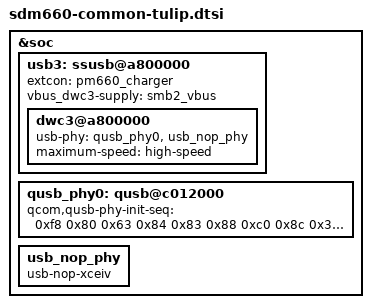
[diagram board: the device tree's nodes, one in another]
/* Copyright (c) 2016-2017, The Linux Foundation. All rights reserved.
 * Copyright (C) 2018 XiaoMi, Inc.
 *
 * This program is free software; you can redistribute it and/or modify
 * it under the terms of the GNU General Public License version 2 and
 * only version 2 as published by the Free Software Foundation.
 *
 * This program is distributed in the hope that it will be useful,
 * but WITHOUT ANY WARRANTY; without even the implied warranty of
 * MERCHANTABILITY or FITNESS FOR A PARTICULAR PURPOSE.  See the
 * GNU General Public License for more details.
 */

&soc {
	usb3: ssusb@a800000 {
		extcon = <&pm660_charger>;
		vbus_dwc3-supply = <&smb2_vbus>;
		dwc3@a800000 {
			usb-phy = <&qusb_phy0>, <&usb_nop_phy>;
			maximum-speed = "high-speed";
		};
	};
	qusb_phy0: qusb@c012000 {
		qcom,qusb-phy-init-seq = <0xf8 0x80
					0x63 0x84
					0x83 0x88
					0xc0 0x8c
					0x30 0x08
					0x79 0x0c
					0x21 0x10
					0x14 0x9c
					0x9f 0x1c
					0x00 0x18>;
	};
	usb_nop_phy: usb_nop_phy {
		compatible = "usb-nop-xceiv";
	};
};
